# HDSC_HC32F030 register map
Vendor: HDSC Co.Ltd; Series: ARMCM0P; File version: 1.2
CPU: CM0 r0p0, little endian, no MPU, no FPU, 3 interrupt priority bits
Registers are 32-bit, read-write, reset 0x0 unless marked. A register's access mark holds for its fields unless they carry their own. Offsets are from the block's base; [hi:lo] are bit positions.

## SPI0 — desc SPI
Base 0x40000800
Same registers: SPI1 0x40004800
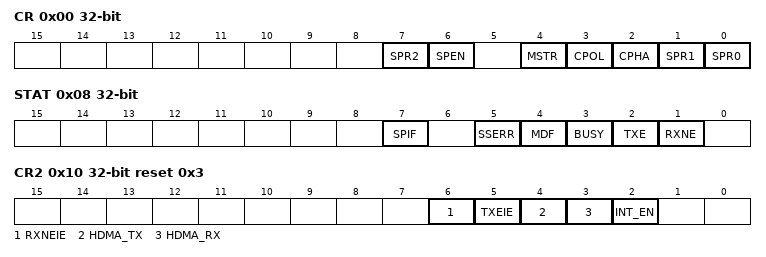
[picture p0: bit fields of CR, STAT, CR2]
0x00 CR
  [7] SPR2, [6] SPEN, [4] MSTR, [3] CPOL, [2] CPHA, [1] SPR1, [0] SPR0
0x04 SSN reset 0x1
  [0] SSN
0x08 STAT ro
  [7] SPIF, [5] SSERR, [4] MDF, [3] BUSY, [2] TXE, [1] RXNE
0x0C DATA
  [7:0] DAT
0x10 CR2 reset 0x3
  [6] RXNEIE, [5] TXEIE, [4] HDMA_TX, [3] HDMA_RX, [2] INT_EN
0x14 ICLR wo reset 0xFFFFFFFF
  [0] INT_CLR

## SYSCTRL
Base 0x40002000
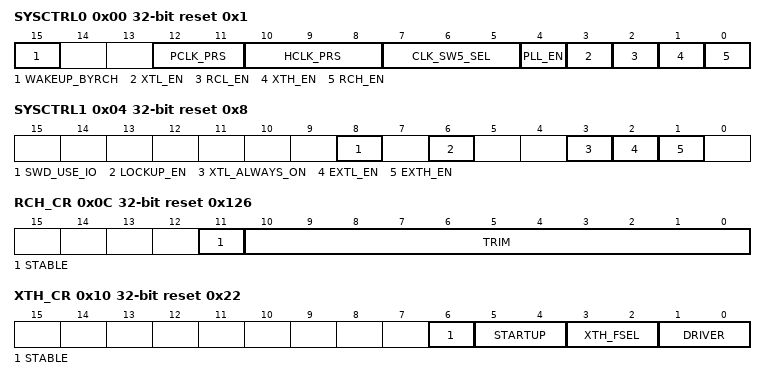
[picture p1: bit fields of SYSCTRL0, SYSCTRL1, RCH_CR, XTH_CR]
0x00 SYSCTRL0 reset 0x1
  [15] WAKEUP_BYRCH, [12:11] PCLK_PRS, [10:8] HCLK_PRS, [7:5] CLK_SW5_SEL, [4] PLL_EN, [3] XTL_EN, [2] RCL_EN, [1] XTH_EN, [0] RCH_EN
0x04 SYSCTRL1 reset 0x8
  [8] SWD_USE_IO, [6] LOCKUP_EN, [3] XTL_ALWAYS_ON, [2] EXTL_EN, [1] EXTH_EN
0x08 SYSCTRL2 wo
  [15:0] SYSCTRL2
0x0C RCH_CR reset 0x126
  [11] STABLE ro, [10:0] TRIM
0x10 XTH_CR reset 0x22
  [6] STABLE ro, [5:4] STARTUP, [3:2] XTH_FSEL, [1:0] DRIVER
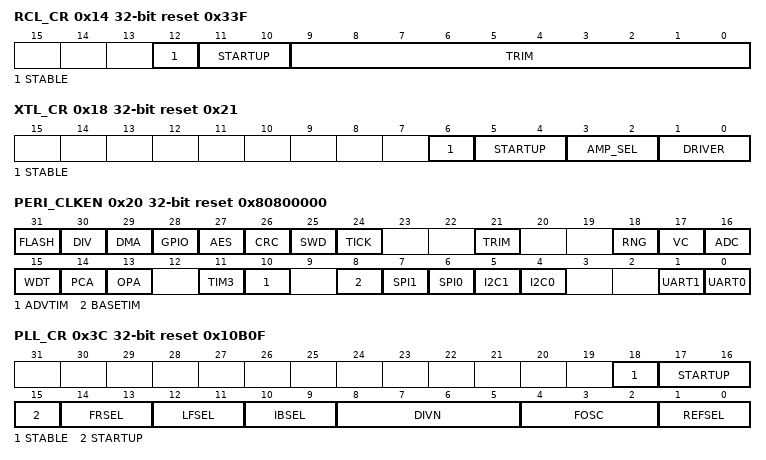
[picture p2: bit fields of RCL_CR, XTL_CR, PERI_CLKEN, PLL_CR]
0x14 RCL_CR reset 0x33F
  [12] STABLE ro, [11:10] STARTUP, [9:0] TRIM
0x18 XTL_CR reset 0x21
  [6] STABLE ro, [5:4] STARTUP, [3:2] AMP_SEL, [1:0] DRIVER
0x20 PERI_CLKEN reset 0x80800000
  [31] FLASH, [30] DIV, [29] DMA, [28] GPIO, [27] AES, [26] CRC, [25] SWD, [24] TICK, [21] TRIM, [18] RNG, [17] VC, [16] ADC, [15] WDT, [14] PCA, [13] OPA, [11] TIM3, [10] ADVTIM, [8] BASETIM, [7] SPI1, [6] SPI0, [5] I2C1, [4] I2C0, [1] UART1, [0] UART0
0x3C PLL_CR reset 0x10B0F (reset mask 0x3FFFF)
  [18] STABLE, [17:15] STARTUP, [14:13] FRSEL, [12:11] LFSEL, [10:9] IBSEL, [8:5] DIVN, [4:2] FOSC, [1:0] REFSEL

## TIM0_MODE0
Base 0x40000C00
Same registers: TIM1_MODE0 0x40000D00, TIM2_MODE0 0x40000E00, TIM3_MODE0 0x40005800
0x00 ARR
  [15:0] ARR
0x04 CNT
  [15:0] CNT
0x08 CNT32
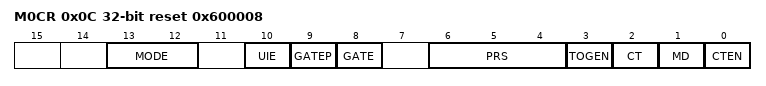
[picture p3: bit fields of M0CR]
0x0C M0CR reset 0x600008
  [13:12] MODE, [10] UIE, [9] GATEP, [8] GATE, [6:4] PRS, [3] TOGEN, [2] CT, [1] MD, [0] CTEN
0x10 IFR ro
  [0] UIF
0x14 ICLR wo reset 0xFFFF
  [0] UIF
0x30 DTR
  [12] MOE

## TIM0_MODE1
Base 0x40000C00; alternate view of TIM0_MODE0
0x04 CNT
  [15:0] CNT
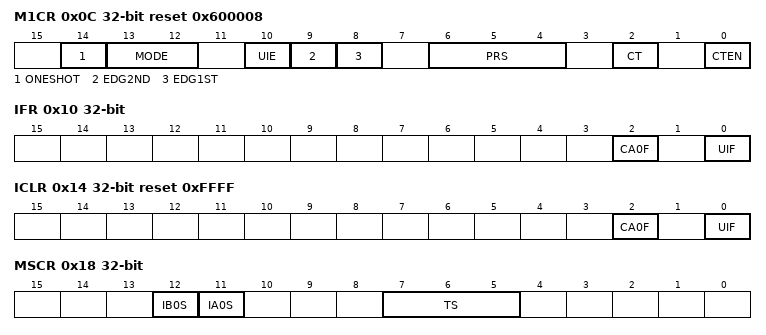
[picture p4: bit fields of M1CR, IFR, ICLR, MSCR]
0x0C M1CR reset 0x600008
  [14] ONESHOT, [13:12] MODE, [10] UIE, [9] EDG2ND, [8] EDG1ST, [6:4] PRS, [2] CT, [0] CTEN
0x10 IFR ro
  [2] CA0F, [0] UIF
0x14 ICLR wo reset 0xFFFF
  [2] CA0F, [0] UIF
0x18 MSCR
  [12] IB0S, [11] IA0S, [7:5] TS
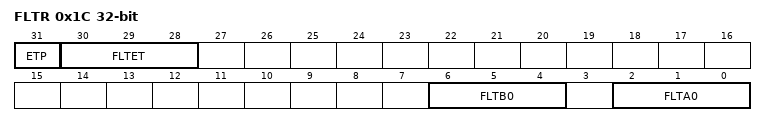
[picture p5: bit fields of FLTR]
0x1C FLTR
  [31] ETP, [30:28] FLTET, [6:4] FLTB0, [2:0] FLTA0
0x24 CR0 reset 0x3000
  [8] CIEA
0x3C CCR0A
  [15:0] CCR0A

## TIM1_MODE1
Base 0x40000D00; alternate view of TIM1_MODE0
Registers as TIM0_MODE1.

## TIM2_MODE1
Base 0x40000E00; alternate view of TIM2_MODE0
Registers as TIM0_MODE1.

## TIM3_MODE1
Base 0x40005800; alternate view of TIM3_MODE0
Registers as TIM0_MODE1.

## TIM0_MODE23
Base 0x40000C00; alternate view of TIM0_MODE0
0x00 ARR
  [15:0] ARR
0x04 CNT
  [15:0] CNT
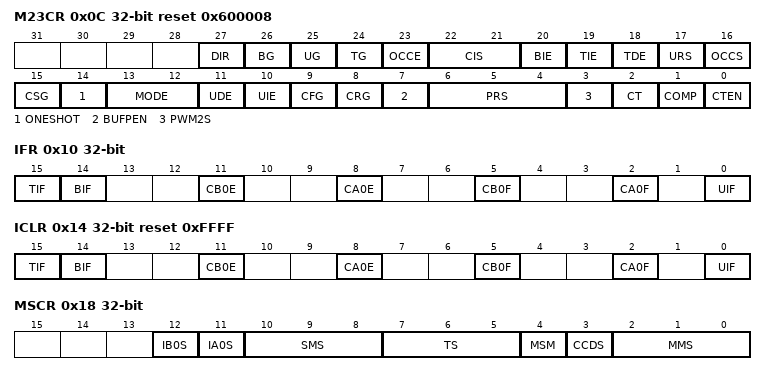
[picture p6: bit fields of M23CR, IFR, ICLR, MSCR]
0x0C M23CR reset 0x600008
  [27] DIR, [26] BG wo, [25] UG wo, [24] TG wo, [23] OCCE, [22:21] CIS, [20] BIE, [19] TIE, [18] TDE, [17] URS, [16] OCCS, [15] CSG, [14] ONESHOT, [13:12] MODE, [11] UDE, [10] UIE, [9] CFG, [8] CRG, [7] BUFPEN, [6:4] PRS, [3] PWM2S, [2] CT, [1] COMP, [0] CTEN
0x10 IFR ro
  [15] TIF, [14] BIF, [11] CB0E, [8] CA0E, [5] CB0F, [2] CA0F, [0] UIF
0x14 ICLR wo reset 0xFFFF
  [15] TIF, [14] BIF, [11] CB0E, [8] CA0E, [5] CB0F, [2] CA0F, [0] UIF
0x18 MSCR
  [12] IB0S, [11] IA0S, [10:8] SMS, [7:5] TS, [4] MSM, [3] CCDS, [2:0] MMS
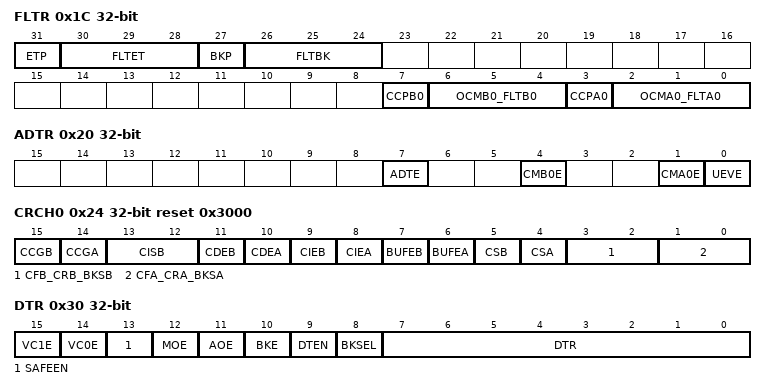
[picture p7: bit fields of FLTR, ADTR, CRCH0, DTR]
0x1C FLTR
  [31] ETP, [30:28] FLTET, [27] BKP, [26:24] FLTBK, [7] CCPB0, [6:4] OCMB0_FLTB0, [3] CCPA0, [2:0] OCMA0_FLTA0
0x20 ADTR
  [7] ADTE, [4] CMB0E, [1] CMA0E, [0] UEVE
0x24 CRCH0 reset 0x3000
  [15] CCGB, [14] CCGA, [13:12] CISB, [11] CDEB, [10] CDEA, [9] CIEB, [8] CIEA, [7] BUFEB, [6] BUFEA, [5] CSB, [4] CSA, [3:2] CFB_CRB_BKSB, [1:0] CFA_CRA_BKSA
0x30 DTR
  [15] VC1E, [14] VC0E, [13] SAFEEN, [12] MOE, [11] AOE, [10] BKE, [9] DTEN, [8] BKSEL, [7:0] DTR
0x34 RCR
  [7:0] RCR
0x38 ARRDM
  [15:0] ARRDM
0x3C CCR0A
  [15:0] CCR0A
0x40 CCR0B
  [15:0] CCR0B

## TIM1_MODE23
Base 0x40000D00; alternate view of TIM1_MODE0
Registers as TIM0_MODE23.

## TIM2_MODE23
Base 0x40000E00; alternate view of TIM2_MODE0
Registers as TIM0_MODE23.
